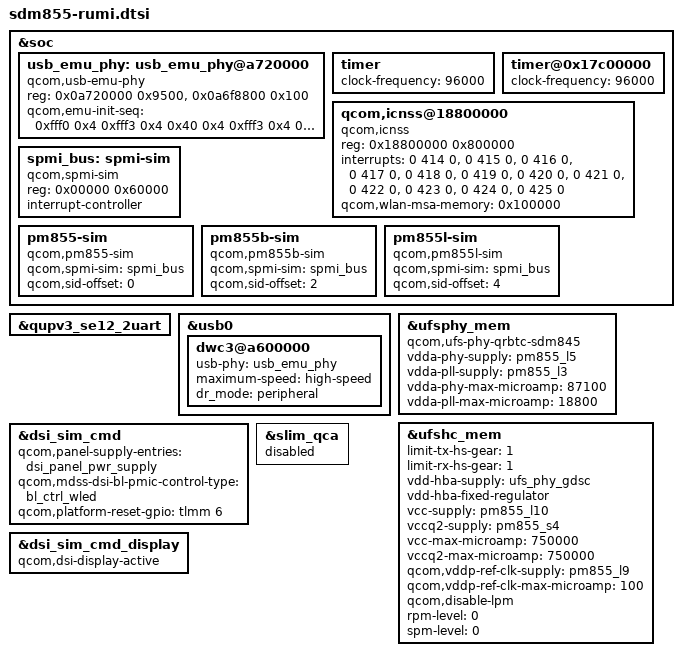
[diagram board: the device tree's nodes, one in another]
/* Copyright (c) 2017, The Linux Foundation. All rights reserved.
 *
 * This program is free software; you can redistribute it and/or modify
 * it under the terms of the GNU General Public License version 2 and
 * only version 2 as published by the Free Software Foundation.
 *
 * This program is distributed in the hope that it will be useful,
 * but WITHOUT ANY WARRANTY; without even the implied warranty of
 * MERCHANTABILITY or FITNESS FOR A PARTICULAR PURPOSE.  See the
 * GNU General Public License for more details.
 */

&soc {
	usb_emu_phy: usb_emu_phy@a720000 {
		compatible = "qcom,usb-emu-phy";
		reg = <0x0a720000 0x9500>,
		      <0x0a6f8800 0x100>;
		reg-names = "base", "qcratch_base";

		qcom,emu-init-seq = <0xfff0 0x4
				     0xfff3 0x4
				     0x40 0x4
				     0xfff3 0x4
				     0xfff0 0x4
				     0x100000 0x20
				     0x0 0x20
				     0x1a0 0x20
				     0x100000 0x3c
				     0x0 0x3c
				     0x10060 0x3c
				     0x0 0x4>;
	};

	timer {
		clock-frequency = <96000>;
	};

	timer@0x17c00000 {
		clock-frequency = <96000>;
	};

	qcom,icnss@18800000 {
		compatible = "qcom,icnss";
		reg = <0x18800000 0x800000>;
		reg-names = "membase";
		interrupts = <0 414 0 /* CE0 */ >,
			     <0 415 0 /* CE1 */ >,
			     <0 416 0 /* CE2 */ >,
			     <0 417 0 /* CE3 */ >,
			     <0 418 0 /* CE4 */ >,
			     <0 419 0 /* CE5 */ >,
			     <0 420 0 /* CE6 */ >,
			     <0 421 0 /* CE7 */ >,
			     <0 422 0 /* CE8 */ >,
			     <0 423 0 /* CE9 */ >,
			     <0 424 0 /* CE10 */ >,
			     <0 425 0 /* CE11 */ >;
		qcom,wlan-msa-memory = <0x100000>;
	};

	spmi_bus: spmi-sim {
		compatible = "qcom,spmi-sim";
		reg = <0x00000 0x60000>;
		#address-cells = <2>;
		#size-cells = <0>;
		interrupt-controller;
		#interrupt-cells = <4>;
	};

	pm855-sim {
		compatible = "qcom,pm855-sim";
		qcom,spmi-sim = <&spmi_bus>;
		qcom,sid-offset = <0>;
	};

	pm855b-sim {
		compatible = "qcom,pm855b-sim";
		qcom,spmi-sim = <&spmi_bus>;
		qcom,sid-offset = <2>;
	};

	pm855l-sim {
		compatible = "qcom,pm855l-sim";
		qcom,spmi-sim = <&spmi_bus>;
		qcom,sid-offset = <4>;
	};
};

#include "sdm855-pmic-overlay.dtsi"

&qupv3_se12_2uart {
	status = "ok";
};

&usb0 {
	dwc3@a600000 {
		usb-phy = <&usb_emu_phy>;
		maximum-speed = "high-speed";
		dr_mode = "peripheral";
	};
};

&ufsphy_mem {
	compatible = "qcom,ufs-phy-qrbtc-sdm845";

	vdda-phy-supply = <&pm855_l5>;
	vdda-pll-supply = <&pm855_l3>;
	vdda-phy-max-microamp = <87100>;
	vdda-pll-max-microamp = <18800>;

	status = "ok";
};

&ufshc_mem {
	limit-tx-hs-gear = <1>;
	limit-rx-hs-gear = <1>;

	vdd-hba-supply = <&ufs_phy_gdsc>;
	vdd-hba-fixed-regulator;
	vcc-supply = <&pm855_l10>;
	vccq2-supply = <&pm855_s4>;
	vcc-max-microamp = <750000>;
	vccq2-max-microamp = <750000>;

	qcom,vddp-ref-clk-supply = <&pm855_l9>;
	qcom,vddp-ref-clk-max-microamp = <100>;

	qcom,disable-lpm;
	rpm-level = <0>;
	spm-level = <0>;
	status = "ok";
};

&dsi_sim_cmd {
	qcom,panel-supply-entries = <&dsi_panel_pwr_supply>;
	qcom,mdss-dsi-bl-pmic-control-type = "bl_ctrl_wled";
	qcom,platform-reset-gpio = <&tlmm 6 0>;
};

&dsi_sim_cmd_display {
	qcom,dsi-display-active;
};

&slim_qca {
	status = "disabled";
};
